# ISD9300_v3 register map
File version: 1.0
Registers are 32-bit, read-write, reset 0x0 unless marked. A register's access mark holds for its fields unless they carry their own. Offsets are from the block's base; [hi:lo] are bit positions; {n}, {i} and the like mark numbered series; 'fields as' and 'values as' point back to an identical list; <NAME> marks a mode.

## PWM — PWM0_PWM1 Register Map
Base 0x40040000
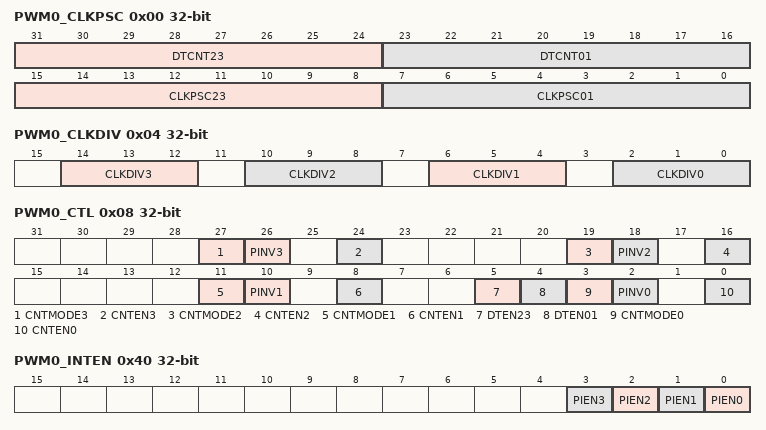
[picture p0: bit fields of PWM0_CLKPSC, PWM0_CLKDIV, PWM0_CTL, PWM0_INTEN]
0x00 PWM0_CLKPSC — PWM Prescaler Register
  [31:24] DTCNT23 — Dead Zone Interval Register For Pair Of PWM0CH2 And PWM0CH3. These 8 bits determine dead zone length. The unit time of dead zone length is that from clock selector 0.
  [23:16] DTCNT01 — Dead Zone Interval Register For Pair Of PWM0CH0 And PWM0CH1. These 8 bits determine dead zone length. The unit time of dead zone length is that from clock selector 0.
  [15:8] CLKPSC23 — Clock Pre-Scaler For Pair Of PWM0CH2 And PWM0CH3. Clock input is divided by (CLKPSC23 + 1). If CLKPSC23 aaa 0, then the pre-scaler output clock will be stopped. This implies PWM counter 2 and 3 will also be stopped.
  [7:0] CLKPSC01 — Clock Pre-Scaler Pair Of PWM0CH0 And PWM0CH1. Clock input is divided by (CLKPSC01 + 1). If CLKPSC01 aaa 0, then the pre-scaler output clock will be stopped. This implies PWM counter 0 and 1 will also be stopped.
0x04 PWM0_CLKDIV — PWM Clock Select Register
  [14:12] CLKDIV3 — Timer 3 Clock Source Selection (Table is as CLKDIV0)
  [10:8] CLKDIV2 — Timer 2 Clock Source Selection (Table is as CLKDIV0)
  [6:4] CLKDIV1 — Timer 1 Clock Source Selection (Table is as CLKDIV0)
  [2:0] CLKDIV0 — Timer 0 Clock Source Selection. Value : Input clock divided by. 0 : 2. 1 : 4. 2 : 8. 3 : 16. 4 : 1
0x08 PWM0_CTL — PWM Control Register
  [27] CNTMODE3 — PWM-Timer 3 Auto-Reload/One-Shot Mode. Note: A rising transition of this bit will cause PWM_PERIOD3 and PWM_CMPDAT3 to be cleared.
    0=One-Shot Mode; 1=Auto-load Mode
  [8n+2] PINV{n} (n=0..3) — PWM-Timer {n} Output Inverter ON/OFF
    0=Inverter OFF; 1=Inverter ON
  [24] CNTEN3 — PWM-Timer 3 Enable/Disable Start Run
    0=Stop PWM-Timer 3; 1=Enable PWM-Timer 3 Start/Run
  [19] CNTMODE2 — PWM-Timer 2 Auto-Reload/One-Shot Mode. Note: A rising transition of this bit will cause PWM_PERIOD2 and PWM_CMPDAT2 to be cleared.
    0=One-Shot Mode; 1=Auto-load Mode
  [16] CNTEN2 — PWM-Timer 2 Enable/Disable Start Run
    0=Stop PWM-Timer 2; 1=Enable PWM-Timer 2 Start/Run
  [11] CNTMODE1 — PWM-Timer 1 Auto-Reload/One-Shot Mode. Note: A rising transition of this bit will cause PWM_PERIOD1 and PWM_CMPDAT1 to be cleared.
    0=One-Shot Mode; 1=Auto-load Mode
  [8] CNTEN1 — PWM-Timer 1 Enable/Disable Start Run
    0=Stop PWM-Timer 1; 1=Enable PWM-Timer 1 Start/Run
  [5] DTEN23 — Dead-Zone 23 Generator Enable/Disable Pair Of PWM0CH2 And PWM0CH3. Note: When Dead-Zone Generator is enabled, the pair of PWM0CH2 and PWM0CH3 become a complementary pair.
    0=Disable; 1=Enable
  [4] DTEN01 — Dead-Zone 01 Generator Enable/Disable Pair Of PWM0CH0 And PWM0CH1. Note: When Dead-Zone Generator is enabled, the pair of PWM0CH0 and PWM0CH1 become a complementary pair.
    0=Disable; 1=Enable
  [3] CNTMODE0 — PWM-Timer 0 Auto-Reload/One-Shot Mode. Note: A rising transition of this bit will cause PWM_PERIOD0 and PWM_CMPDAT0 to be cleared.
    0=One-Shot Mode; 1=Auto-reload Mode
  [0] CNTEN0 — PWM-Timer 0 Enable/Disable Start Run
    0=Stop PWM-Timer 0 Running; 1=Enable PWM-Timer 0 Start/Run
{0xC+0xC*i} PWM0_PERIOD{i} (i=0..3) — PWM Counter Register 0
  [15:0] PERIOD — PWM Counter/Timer Reload Value. PERIOD determines the PWM period. PWM frequency aaa PWM0CHx_CLK/(prescale+1)*(clock divider)/(PERIOD+1); Duty ratio aaa (CMP+1)/(PERIOD+1). CMP > aaa PERIOD: PWM output is always high. CMP < PERIOD: PWM low width aaa (PERIOD-CMP) unit; PWM high width aaa (CMP+1) unit. CMP aaa 0: PWM low width aaa (PERIOD) unit; PWM high width aaa 1 unit (Unit aaa one PWM clock cycle). Note: Any write to PERIOD will take effect in next PWM cycle.
{0x10+0xC*i} PWM0_CMPDAT{i} (i=0..3) — PWM Comparator Register 0
  [15:0] CMP — PWM Comparator Register. CMP determines the PWM duty cycle. PWM frequency aaa PWM0CHx_CLK/(prescale+1)*(clock divider)/(PERIOD+1); Duty Cycle aaa (CMP+1)/(PERIOD+1). CMP > aaa PERIOD: PWM output is always high. CMP < PERIOD: PWM low width aaa (PERIOD-CMP) unit; PWM high width aaa (CMP+1) unit. CMP aaa 0: PWM low width aaa (PERIOD) unit; PWM high width aaa 1 unit (Unit aaa one PWM clock cycle). Note: Any write to CMP will take effect in next PWM cycle.
{0x14+0xC*i} PWM0_CNT{i} ro (i=0..3) — PWM Data Register 0
  [15:0] CNT — PWM Data Register. Reports the current value of the 16-bit down counter.
0x40 PWM0_INTEN — PWM Interrupt Enable Register
  [all] fields
    0=Disable; 1=Enable
  [n] PIEN{n} (n=0..3) — PWM Timer {n} Interrupt Enable
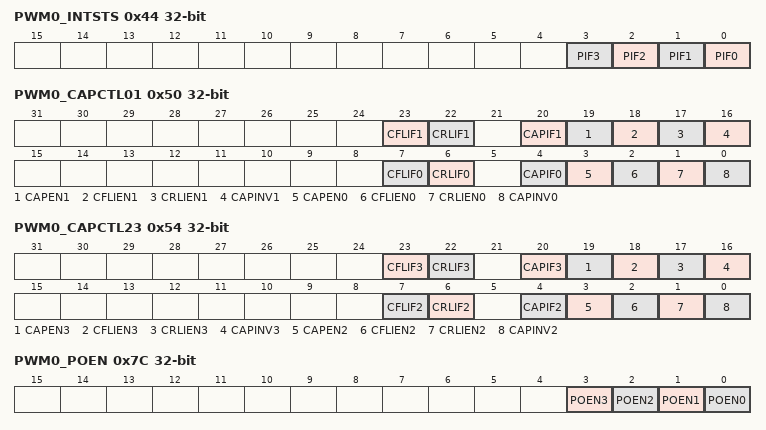
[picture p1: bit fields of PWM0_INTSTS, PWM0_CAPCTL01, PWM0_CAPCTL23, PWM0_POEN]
0x44 PWM0_INTSTS — PWM Interrupt Flag Register
  [n] PIF{n} (n=0..3) — PWM Timer {n} Interrupt Flag. Flag is set by hardware when PWM0CH{n} down counter reaches zero, software can clear this bit by writing '1' to it.
0x50 PWM0_CAPCTL01 — Capture Control Register For Pair Of PWM0CH0 And PWM0CH1
  [23] CFLIF1 — PWM_FCAPDAT1 Latched Indicator Bit. When input channel 1 has a falling transition, PWM_FCAPDAT1 was latched with the value of PWM down-counter and this bit is set by hardware, software can clear this bit by writing a zero to it.
  [22] CRLIF1 — PWM_RCAPDAT1 Latched Indicator Bit. When input channel 1 has a rising transition, PWM_RCAPDAT1 was latched with the value of PWM down-counter and this bit is set by hardware, software can clear this bit by writing a zero to it.
  [20] CAPIF1 — Capture1 Interrupt Indication Flag. If channel 1 rising latch interrupt is enabled (CRLIEN1 aaa 1), a rising transition at input channel 1 will result in CAPIF1 to high; Similarly, a falling transition will cause CAPIF1 to be set high if channel 1 falling latch interrupt is enabled (CFLIEN1 aaa 1). This flag is cleared by software writing a '1' to it.
  [19] CAPEN1 — Capture Channel 1 Transition Enable/Disable. When enabled, Capture function latches the PMW-counter to RCAPDAT (Rising latch) and FCAPDAT (Falling latch) registers on input edge transition. When disabled, Capture function is inactive as is interrupt.
    0=Disable capture function on channel 1; 1=Enable capture function on channel 1
  [18] CFLIEN1 — Channel 1 Falling Latch Interrupt Enable. When enabled, capture block generates an interrupt on falling edge of input.
    0=Disable falling edge latch interrupt; 1=Enable falling edge latch interrupt
  [17] CRLIEN1 — Channel 1 Rising Latch Interrupt Enable. When enabled, capture block generates an interrupt on rising edge of input.
    0=Disable rising edge latch interrupt; 1=Enable rising edge latch interrupt
  [16] CAPINV1 — Channel 1 Inverter ON/OFF
    0=Inverter OFF; 1=Inverter ON. Reverse the input signal from GPIO before Capture timer
  [7] CFLIF0 — PWM_FCAPDAT0 Latched Indicator Bit. When input channel 0 has a falling transition, PWM_FCAPDAT0 was latched with the value of PWM down-counter and this bit is set by hardware, software can clear this bit by writing a zero to it.
  [6] CRLIF0 — PWM_RCAPDAT0 Latched Indicator Bit. When input channel 0 has a rising transition, PWM_RCAPDAT0 was latched with the value of PWM down-counter and this bit is set by hardware, software can clear this bit by writing a zero to it.
  [4] CAPIF0 — Capture0 Interrupt Indication Flag. If channel 0 rising latch interrupt is enabled (CRLIEN0 aaa 1), a rising transition at input channel 0 will result in CAPIF0 to high; Similarly, a falling transition will cause CAPIF0 to be set high if channel 0 falling latch interrupt is enabled (CFLIEN0 aaa 1). This flag is cleared by software writing a '1' to it.
  [3] CAPEN0 — Capture Channel 0 Transition Enable/Disable. When enabled, Capture function latches the PMW-counter to RCAPDAT (Rising latch) and FCAPDAT (Falling latch) registers on input edge transition. When disabled, Capture function is inactive as is interrupt.
    0=Disable capture function on channel 0; 1=Enable capture function on channel 0
  [2] CFLIEN0 — Channel 0 Falling Latch Interrupt Enable ON/OFF. When enabled, capture block generates an interrupt on falling edge of input.
    0=Disable falling latch interrupt; 1=Enable falling latch interrupt
  [1] CRLIEN0 — Channel 0 Rising Latch Interrupt Enable ON/OFF. When enabled, capture block generates an interrupt on rising edge of input.
    0=Disable rising latch interrupt; 1=Enable rising latch interrupt
  [0] CAPINV0 — Channel 0 Inverter ON/OFF
    values as CAPINV1
0x54 PWM0_CAPCTL23 — Capture Control Register For Pair Of PWM0CH2 And PWM0CH3
  [23] CFLIF3 — PWM_FCAPDAT3 Latched Indicator Bit. When input channel 1 has a falling transition, PWM_FCAPDAT3 was latched with the value of PWM down-counter and this bit is set by hardware, software can clear this bit by writing a zero to it.
  [22] CRLIF3 — PWM_RCAPDAT3 Latched Indicator Bit. When input channel 1 has a rising transition, PWM_RCAPDAT3 was latched with the value of PWM down-counter and this bit is set by hardware, software can clear this bit by writing a zero to it.
  [20] CAPIF3 — Capture3 Interrupt Indication Flag. If channel 1 rising latch interrupt is enabled (CRLIEN3 aaa 1), a rising transition at input channel 1 will result in CAPIF3 to high; Similarly, a falling transition will cause CAPIF3 to be set high if channel 1 falling latch interrupt is enabled (CFLIEN3 aaa 1). This flag is cleared by software writing a '1' to it.
  [19] CAPEN3 — Capture Channel 3 Transition Enable/Disable. When enabled, Capture function latches the PMW-counter to RCAPDAT (Rising latch) and FCAPDAT (Falling latch) registers on input edge transition. When disabled, Capture function is inactive as is interrupt.
    values as PWM0_CAPCTL01.CAPEN1
  [18] CFLIEN3 — Channel 3 Falling Latch Interrupt Enable. When enabled, capture block generates an interrupt on falling edge of input.
    values as PWM0_CAPCTL01.CFLIEN1
  [17] CRLIEN3 — Channel 3 Rising Latch Interrupt Enable. When enabled, capture block generates an interrupt on rising edge of input.
    values as PWM0_CAPCTL01.CRLIEN1
  [16] CAPINV3 — Channel 3 Inverter ON/OFF
    values as PWM0_CAPCTL01.CAPINV1
  [7] CFLIF2 — PWM_FCAPDAT2 Latched Indicator Bit. When input channel 0 has a falling transition, PWM_FCAPDAT2 was latched with the value of PWM down-counter and this bit is set by hardware, software can clear this bit by writing a zero to it.
  [6] CRLIF2 — PWM_RCAPDAT2 Latched Indicator Bit. When input channel 0 has a rising transition, PWM_RCAPDAT2 was latched with the value of PWM down-counter and this bit is set by hardware, software can clear this bit by writing a zero to it.
  [4] CAPIF2 — Capture2 Interrupt Indication Flag. If channel 0 rising latch interrupt is enabled (CRLIEN2 aaa 1), a rising transition at input channel 0 will result in CAPIF2 to high; Similarly, a falling transition will cause CAPIF2 to be set high if channel 0 falling latch interrupt is enabled (CFLIEN2 aaa 1). This flag is cleared by software writing a '1' to it.
  [3] CAPEN2 — Capture Channel 2 Transition Enable/Disable. When enabled, Capture function latches the PMW-counter to RCAPDAT (Rising latch) and FCAPDAT (Falling latch) registers on input edge transition. When disabled, Capture function is inactive as is interrupt.
    values as PWM0_CAPCTL01.CAPEN0
  [2] CFLIEN2 — Channel 2 Falling Latch Interrupt Enable ON/OFF. When enabled, capture block generates an interrupt on falling edge of input.
    values as PWM0_CAPCTL01.CFLIEN0
  [1] CRLIEN2 — Channel 2 Rising Latch Interrupt Enable ON/OFF. When enabled, capture block generates an interrupt on rising edge of input.
    values as PWM0_CAPCTL01.CRLIEN0
  [0] CAPINV2 — Channel 2 Inverter ON/OFF
    values as PWM0_CAPCTL01.CAPINV1
{0x58+8i} PWM0_RCAPDAT{i} ro (i=0..3) — Capture Rising Latch Register (Channel 0)
  [15:0] RCAPDAT — Capture Rising Latch Register. In Capture mode, this register is latched with the value of the PWM counter on a rising edge of the input signal.
{0x5C+8i} PWM0_FCAPDAT{i} ro (i=0..3) — Capture Falling Latch Register (Channel 0)
  [15:0] FCAPDAT — Capture Falling Latch Register. In Capture mode, this register is latched with the value of the PWM counter on a falling edge of the input signal.
0x78 PWM0_CAPINEN — Capture Input Enable Register
  [3:0] CAPINEN — Capture Input Enable Register. 0 : OFF (GPA[13:12], GPB[15:14] pin input disconnected from Capture block). 1 : ON (GPA[13:12] , GPB[15:14] pin, if in PWM alternative function, will be configured as an input and fed to capture function). CAPINEN[3:0]. Bit [3][2][1][0]. Bit xxx1 : Capture channel 0 is from GPA [12]. Bit xx1x : Capture channel 1 is from GPA [13]. Bit x1xx : Capture channel 2 is from GPB [14]. Bit 1xxx : Capture channel 3 is from GPB [15]
0x7C PWM0_POEN — PWM0 Output Enable Register for CH0~CH3
  [3] POEN3 — PWM0CH3 Output Enable Register. Note: The corresponding GPIO pin also must be switched to PWM function (refer to SYS_GPA_MFP Table 57)
    0=Disable PWM0CH3 output to pin; 1=Enable PWM0CH3 output to pin
  [2] POEN2 — PWM0CH2 Output Enable Register. Note: The corresponding GPIO pin also must be switched to PWM function (refer to SYS_GPA_MFP Table 57)
    0=Disable PWM0CH2 output to pin; 1=Enable PWM0CH2 output to pin
  [1] POEN1 — PWM0CH1 Output Enable Register. Note: The corresponding GPIO pin also must be switched to PWM function (refer to SYS_GPA_MFP Table 57)
    0=Disable PWM0CH1 output to pin; 1=Enable PWM0CH1 output to pin
  [0] POEN0 — PWM0CH0 Output Enable Register. Note: The corresponding GPIO pin also must be switched to PWM function (refer to SYS_GPA_MFP Table 57)
    0=Disable PWM0CH0 output to pin; 1=Enable PWM0CH 0 output to pin
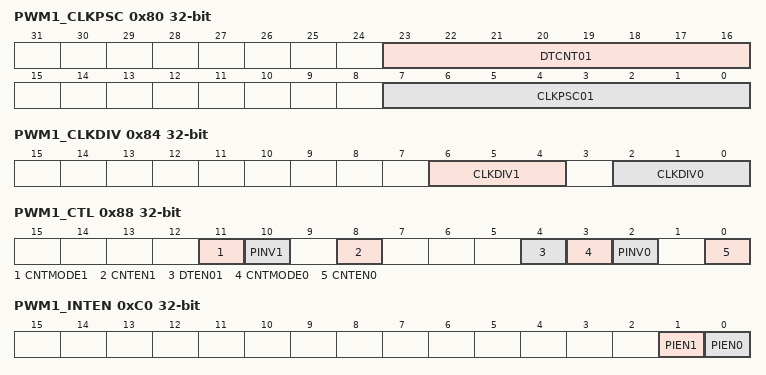
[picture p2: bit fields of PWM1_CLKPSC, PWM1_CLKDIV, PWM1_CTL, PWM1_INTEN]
0x80 PWM1_CLKPSC — PWM Prescaler Register
  [23:16] DTCNT01 — Dead Zone Interval Register For Pair Of PWM1CH0 And PWM1CH1. These 8 bits determine dead zone length. The unit time of dead zone length is that from clock selector 0.
  [7:0] CLKPSC01 — Clock Pre-Scaler For Pair Of PWM1CH0 And PWM1CH1. Clock input is divided by (CLKPSC01 + 1). If CLKPSC01 aaa 0, then the pre-scaler output clock will be stopped. This implies PWM counter 4 and 5 will also be stopped.
0x84 PWM1_CLKDIV — PWM Clock Select Register
  [6:4] CLKDIV1 — Timer 1 Clock Source Selection (Table is as CLKDIV0)
  [2:0] CLKDIV0 — Timer 0 Clock Source Selection. Value : Input clock divided by. 0 : 2. 1 : 4. 2 : 8. 3 : 16. 4 : 1
0x88 PWM1_CTL — PWM Control Register
  [11] CNTMODE1 — PWM-Timer 1 Auto-Reload/One-Shot Mode. Note: A rising transition of this bit will cause PWM_PERIOD1 and PWM_CMPDAT1 to be cleared.
    0=One-Shot Mode; 1=Auto-load Mode
  [10] PINV1 — PWM-Timer 1 Output Inverter ON/OFF
    0=Inverter OFF; 1=Inverter ON
  [8] CNTEN1 — PWM-Timer 1 Enable/Disable Start Run
    0=Stop PWM-Timer 1; 1=Enable PWM-Timer 1 Start/Run
  [4] DTEN01 — Dead-Zone 01 Generator Enable/Disable For Pair Of PWM1CH0 And PWM1CH1. Note: When Dead-Zone Generator is enabled, the pair of PWM1CH0 and PWM1CH1 become a complementary pair.
    0=Disable; 1=Enable
  [3] CNTMODE0 — PWM-Timer 0 Auto-Reload/One-Shot Mode. Note: A rising transition of this bit will cause PWM_PERIOD0 and PWM_CMPDAT0 to be cleared.
    0=One-Shot Mode; 1=Auto-reload Mode
  [2] PINV0 — PWM-Timer 0 Output Inverter ON/OFF
    0=Inverter OFF; 1=Inverter ON
  [0] CNTEN0 — PWM-Timer 0 Enable/Disable Start Run
    0=Stop PWM-Timer 0 Running; 1=Enable PWM-Timer 0 Start/Run
0x8C PWM1_PERIOD0 — PWM Counter Register 0
  [15:0] PERIOD — PWM Counter/Timer Reload Value. PERIOD determines the PWM period. PWM frequency aaa PWM1CH01_CLK/(prescale+1)*(clock divider)/(PERIOD+1); Duty ratio aaa (CMP+1)/(PERIOD+1). CMP > aaa PERIOD: PWM output is always high. CMP < PERIOD: PWM low width aaa (PERIOD-CMP) unit; PWM high width aaa (CMP+1) unit. CMP aaa 0: PWM low width aaa (PERIOD) unit; PWM high width aaa 1 unit (Unit aaa one PWM clock cycle). Note: Any write to PERIOD will take effect in next PWM cycle.
0x90 PWM1_CMPDAT0 — PWM Comparator Register 0
  [15:0] CMP — PWM Comparator Register. CMP determines the PWM duty cycle. PWM frequency aaa PWM1CH01_CLK/(prescale+1)*(clock divider)/(PERIOD+1); Duty Cycle aaa (CMP+1)/(PERIOD+1). CMP > aaa PERIOD: PWM output is always high. CMP < PERIOD: PWM low width aaa (PERIOD-CMP) unit; PWM high width aaa (CMP+1) unit. CMP aaa 0: PWM low width aaa (PERIOD) unit; PWM high width aaa 1 unit (Unit aaa one PWM clock cycle). Note: Any write to CMP will take effect in next PWM cycle.
0x94 PWM1_CNT0 ro — PWM Data Register 0
  fields as PWM0_CNT0
0x98 PWM1_PERIOD1 — PWM Counter Register 0
  fields as PWM1_PERIOD0
0x9C PWM1_CMPDAT1 — PWM Comparator Register 0
  fields as PWM1_CMPDAT0
0xA0 PWM1_CNT1 ro — PWM Data Register 0
  fields as PWM0_CNT0
0xC0 PWM1_INTEN — PWM Interrupt Enable Register
  [1] PIEN1 — PWM Timer 1 Interrupt Enable
    0=Disable; 1=Enable
  [0] PIEN0 — PWM Timer 0 Interrupt Enable
    0=Disable; 1=Enable
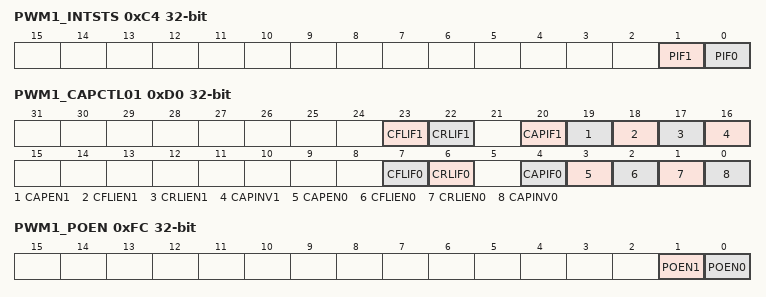
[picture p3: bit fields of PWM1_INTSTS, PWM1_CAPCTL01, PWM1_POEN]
0xC4 PWM1_INTSTS — PWM Interrupt Flag Register
  [1] PIF1 — PWM Timer 1 Interrupt Flag. Flag is set by hardware when PWM1CH1 down counter reaches zero, software can clear this bit by writing '1' to it.
  [0] PIF0 — PWM Timer 0 Interrupt Flag. Flag is set by hardware when PWM1CH0 down counter reaches zero, software can clear this bit by writing '1' to it.
0xD0 PWM1_CAPCTL01 — Capture Control Register For Pair Of PWM1CH0 And PWM1CH1
  fields as PWM0_CAPCTL01
0xD8 PWM1_RCAPDAT0 ro — Capture Rising Latch Register (Channel 0)
  fields as PWM0_RCAPDAT0
0xDC PWM1_FCAPDAT0 ro — Capture Falling Latch Register (Channel 0)
  fields as PWM0_FCAPDAT0
0xE0 PWM1_RCAPDAT1 ro — Capture Rising Latch Register (Channel 0)
  fields as PWM0_RCAPDAT0
0xE4 PWM1_FCAPDAT1 ro — Capture Falling Latch Register (Channel 0)
  fields as PWM0_FCAPDAT0
0xF8 PWM1_CAPINEN — Capture Input Enable Register
  [1:0] CAPINEN — Capture Input Enable Register. 0 : OFF (GPA[15:14] pin input disconnected from Capture block). 1 : ON (GPA[15:14] pin, if in PWM alternative function, will be configured as an input and fed to capture function). CAPINEN[1:0]. Bit [1][0]. Bit x1 : Capture channel 0 is from GPA [14]. Bit 1x : Capture channel 1 is from GPA [15]
0xFC PWM1_POEN — PWM1 Output Enable Register for CH0~CH1
  [1] POEN1 — PWM1CH1 Output Enable Register. Note: The corresponding GPIO pin also must be switched to PWM function (refer to SYS_GPA_MFP Table 57)
    0=Disable PWM1CH1 output to pin; 1=Enable PWM1CH1 output to pin
  [0] POEN0 — PWM1CH0 Output Enable Register. Note: The corresponding GPIO pin also must be switched to PWM function (refer to SYS_GPA_MFP Table 57)
    0=Disable PWM1CH0 output to pin; 1=Enable PWM1CH0 output to pin
